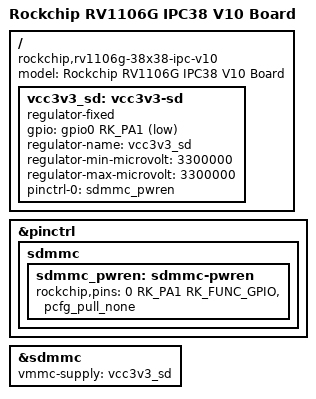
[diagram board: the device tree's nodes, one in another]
// SPDX-License-Identifier: (GPL-2.0+ OR MIT)
/*
 * Copyright (c) 2022 Rockchip Electronics Co., Ltd.
 */

/dts-v1/;

#include "rv1106.dtsi"
#include "rv1106-evb.dtsi"
#include "rv1106-ipc.dtsi"

/ {
	model = "Rockchip RV1106G IPC38 V10 Board";
	compatible = "rockchip,rv1106g-38x38-ipc-v10", "rockchip,rv1106";

	vcc3v3_sd: vcc3v3-sd {
		compatible = "regulator-fixed";
		gpio = <&gpio0 RK_PA1 GPIO_ACTIVE_LOW>;
		regulator-name = "vcc3v3_sd";
		regulator-min-microvolt = <3300000>;
		regulator-max-microvolt = <3300000>;
		pinctrl-names = "default";
		pinctrl-0 = <&sdmmc_pwren>;
	};
};

&pinctrl {
	sdmmc {
		/omit-if-no-ref/
		sdmmc_pwren: sdmmc-pwren {
			rockchip,pins = <0 RK_PA1 RK_FUNC_GPIO &pcfg_pull_none>;
		};
	};
};

&sdmmc {
	vmmc-supply = <&vcc3v3_sd>;
};
